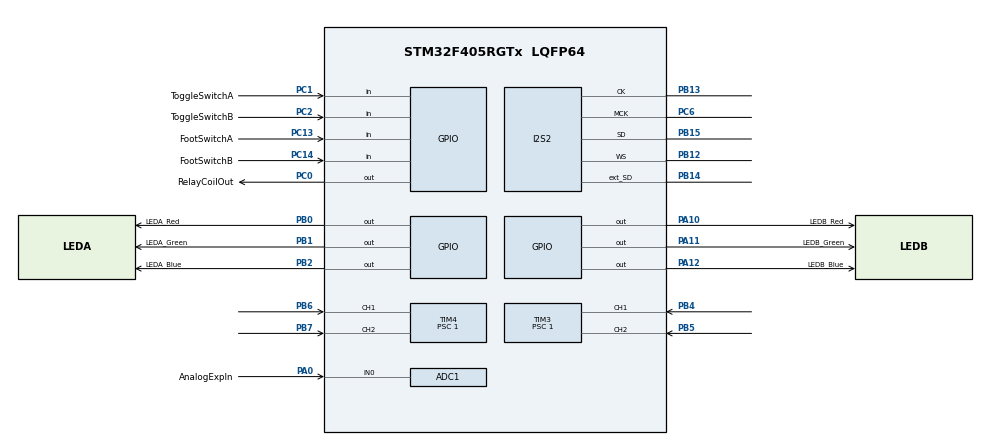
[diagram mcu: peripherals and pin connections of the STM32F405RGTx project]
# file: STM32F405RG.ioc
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Mcu.Family=STM32F4
Dma.I2S2_EXT_RX.1.PeriphInc=DMA_PINC_DISABLE
Dma.SPI2_TX.0.MemInc=DMA_MINC_ENABLE
RCC.CortexFreq_Value=168000000
TIM14.AutoReloadPreload=TIM_AUTORELOAD_PRELOAD_ENABLE
PC0.GPIO_Label=RelayCoilOut
PB0.GPIO_Label=LEDA_Red
NVIC.DMA1_Stream4_IRQn=true\:2\:0\:true\:false\:true\:false\:true
PB13.Signal=I2S2_CK
PB15.Signal=I2S2_SD
Dma.SPI2_TX.0.Instance=DMA1_Stream4
RCC.SYSCLKSource=RCC_SYSCLKSOURCE_PLLCLK
ProjectManager.StackSize=0x400
Dma.SPI2_TX.0.MemDataAlignment=DMA_MDATAALIGN_HALFWORD
Dma.I2S2_EXT_RX.1.Instance=DMA1_Stream3
PA12.Signal=GPIO_Output
RCC.HCLKFreq_Value=168000000
RCC.APB2TimFreq_Value=168000000
PB6.Signal=S_TIM4_CH1
Dma.SPI2_TX.0.Mode=DMA_CIRCULAR
RCC.AHBFreq_Value=168000000
ADC1.Channel-0\#ChannelRegularConversion=ADC_CHANNEL_0
RCC.HSE_VALUE=25000000
NVIC.TIM8_TRG_COM_TIM14_IRQn=true\:0\:0\:false\:false\:true\:true\:true
PB2.Signal=GPIO_Output
PB3.Mode=Trace_Asynchronous_SW
PC13-ANTI_TAMP.Signal=GPIO_Input
TIM14.Period=65535
PA14.Mode=Trace_Asynchronous_SW
PB14.Mode=Full_Duplex_Master
TIM3.Prescaler=1
PB1.GPIO_Label=LEDA_Green
PA10.GPIO_Label=LEDB_Red
SH.S_TIM4_CH2.0=TIM4_CH2,Encoder_Interface
PB7.Signal=S_TIM4_CH2
Dma.I2S2_EXT_RX.1.MemInc=DMA_MINC_ENABLE
SH.ADCx_IN0.0=ADC1_IN0,IN0
SH.S_TIM3_CH1.0=TIM3_CH1,Encoder_Interface
I2S2.DataFormat=I2S_DATAFORMAT_24B
ADC1.SamplingTime-0\#ChannelRegularConversion=ADC_SAMPLETIME_3CYCLES
Mcu.Package=LQFP64
PB1.Signal=GPIO_Output
PB12.Mode=Full_Duplex_Master
PA10.Signal=GPIO_Output
Dma.I2S2_EXT_RX.1.PeriphDataAlignment=DMA_PDATAALIGN_HALFWORD
Dma.SPI2_TX.0.PeriphInc=DMA_PINC_DISABLE
RCC.APB2CLKDivider=RCC_HCLK_DIV2
SH.S_TIM4_CH1.0=TIM4_CH1,Encoder_Interface
Dma.Request1=I2S2_EXT_RX
RCC.APB1TimFreq_Value=84000000
Dma.I2S2_EXT_RX.1.Priority=DMA_PRIORITY_LOW
PC14-OSC32_IN.GPIO_Label=FootSwitchB
PB13.Mode=Full_Duplex_Master
VP_TIM14_VS_ClockSourceINT.Mode=Enable_Timer
Dma.Request0=SPI2_TX
PC6.GPIO_Speed=GPIO_SPEED_FREQ_VERY_HIGH
PC2.GPIO_Label=ToggleSwitchB
PB4.Signal=S_TIM3_CH1
I2S2.AudioFreq=I2S_AUDIOFREQ_96K
ADC1.Rank-0\#ChannelRegularConversion=1
I2S2.Instance=SPI$Index
TIM3.AutoReloadPreload=TIM_AUTORELOAD_PRELOAD_ENABLE
PC13-ANTI_TAMP.GPIO_Label=FootSwitchA
PC2.Signal=GPIO_Input
PC6.Signal=I2S2_MCK
PA11.GPIO_Label=LEDB_Green
PC0.Signal=GPIO_Output
RCC.APB1CLKDivider=RCC_HCLK_DIV4
PC14-OSC32_IN.Signal=GPIO_Input
PA12.GPIO_Label=LEDB_Blue
PA0-WKUP.GPIO_Label=AnalogExpIn
PA0-WKUP.Signal=ADCx_IN0
PA13.Signal=SYS_JTMS-SWDIO
Dma.I2S2_EXT_RX.1.Mode=DMA_CIRCULAR
ProjectManager.TargetToolchain=STM32CubeIDE
PB14.GPIO_Speed=GPIO_SPEED_FREQ_VERY_HIGH
PC6.Mode=Master_Clock_Activated
I2S2.VirtualMode=I2S_MODE_MASTER
PB13.GPIO_Speed=GPIO_SPEED_FREQ_VERY_HIGH
TIM4.Prescaler=1
RCC.LSE_VALUE=32768
PB12.GPIO_Speed=GPIO_SPEED_FREQ_VERY_HIGH
PB14.Signal=I2S2_ext_SD
SH.S_TIM3_CH2.0=TIM3_CH2,Encoder_Interface
Dma.I2S2_EXT_RX.1.FIFOMode=DMA_FIFOMODE_DISABLE
board=custom
RCC.VCOOutputFreq_Value=336000000
PB15.Mode=Full_Duplex_Master
RCC.APB2Freq_Value=84000000
Dma.SPI2_TX.0.PeriphDataAlignment=DMA_PDATAALIGN_HALFWORD
PB15.GPIO_Speed=GPIO_SPEED_FREQ_VERY_HIGH
PC1.GPIO_Label=ToggleSwitchA
PA13.Mode=Trace_Asynchronous_SW
Mcu.Name=STM32F405RGTx
Dma.SPI2_TX.0.FIFOMode=DMA_FIFOMODE_DISABLE
TIM14.Prescaler=4096
I2S2.FullDuplexMode=I2S_FULLDUPLEXMODE_ENABLE
RCC.48MHZClocksFreq_Value=84000000
PB3.Signal=SYS_JTDO-SWO
Dma.SPI2_TX.0.Priority=DMA_PRIORITY_LOW
RCC.SYSCLKFreq_VALUE=168000000
PB5.Signal=S_TIM3_CH2
ADC1.master=1
I2S2.ErrorAudioFreq=-2.34 %
PA11.Signal=GPIO_Output
PA14.Signal=SYS_JTCK-SWCLK
PB2.GPIO_Label=LEDA_Blue
ProjectManager.HeapSize=0x200
RCC.HSI_VALUE=16000000
Dma.I2S2_EXT_RX.1.Direction=DMA_PERIPH_TO_MEMORY
NVIC.PriorityGroup=NVIC_PRIORITYGROUP_4
ADC1.NbrOfConversionFlag=1
RCC.PLLN=336
NVIC.DMA1_Stream3_IRQn=true\:2\:0\:true\:false\:true\:false\:true
Dma.SPI2_TX.0.Direction=DMA_MEMORY_TO_PERIPH
Dma.I2S2_EXT_RX.1.MemDataAlignment=DMA_MDATAALIGN_HALFWORD
RCC.APB1Freq_Value=42000000
PB0.Signal=GPIO_Output
I2S2.RealAudioFreq=93.75 KHz
PC1.Signal=GPIO_Input
PB12.Signal=I2S2_WS

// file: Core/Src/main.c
/* USER CODE BEGIN Header */
/**
  ******************************************************************************
  * @file           : main.c
  * @brief          : Main program body
  ******************************************************************************
  * @attention
  *
  * <h2><center>&copy; Copyright (c) 2022 STMicroelectronics.
  * All rights reserved.</center></h2>
  *
  * This software component is licensed by ST under BSD 3-Clause license,
  * the "License"; You may not use this file except in compliance with the
  * License. You may obtain a copy of the License at:
  *                        opensource.org/licenses/BSD-3-Clause
  *
  ******************************************************************************
  */
/* USER CODE END Header */
#include "main.h"
#include "adc.h"
#include "dma.h"
#include "i2s.h"
#include "tim.h"
#include "gpio.h"

/* USER CODE BEGIN Includes */
#include <mainapp.hpp>
/* USER CODE END Includes */

void SystemClock_Config(void);

int main(void)
{

  /* MCU Configuration--------------------------------------------------------*/

  /* Reset of all peripherals, Initializes the Flash interface and the Systick. */
  HAL_Init();

  /* Configure the system clock */
  SystemClock_Config();

  /* Initialize all configured peripherals */
  MX_GPIO_Init();
  MX_DMA_Init();
  MX_ADC1_Init();
  MX_I2S2_Init();
  MX_TIM3_Init();
  MX_TIM4_Init();
  MX_TIM14_Init();
  /* USER CODE BEGIN 2 */
  mainapp();

  /* USER CODE END 2 */

  /* Infinite loop */
  while (1)
  {

  }
}

void SystemClock_Config(void)
{
  LL_FLASH_SetLatency(LL_FLASH_LATENCY_5);
  while(LL_FLASH_GetLatency()!= LL_FLASH_LATENCY_5)
  {
  }
  LL_PWR_SetRegulVoltageScaling(LL_PWR_REGU_VOLTAGE_SCALE1);
  LL_RCC_HSI_SetCalibTrimming(16);
  LL_RCC_HSI_Enable();

   /* Wait till HSI is ready */
  while(LL_RCC_HSI_IsReady() != 1)
  {

  }
  LL_RCC_PLL_ConfigDomain_SYS(LL_RCC_PLLSOURCE_HSI, LL_RCC_PLLM_DIV_16, 336, LL_RCC_PLLP_DIV_2);
  LL_RCC_PLLI2S_ConfigDomain_I2S(LL_RCC_PLLSOURCE_HSI, LL_RCC_PLLI2SM_DIV_16, 192, LL_RCC_PLLI2SR_DIV_2);
  LL_RCC_PLL_Enable();

   /* Wait till PLL is ready */
  while(LL_RCC_PLL_IsReady() != 1)
  {

  }
  LL_RCC_PLLI2S_Enable();

   /* Wait till PLL is ready */
  while(LL_RCC_PLLI2S_IsReady() != 1)
  {

  }
  LL_RCC_SetAHBPrescaler(LL_RCC_SYSCLK_DIV_1);
  LL_RCC_SetAPB1Prescaler(LL_RCC_APB1_DIV_4);
  LL_RCC_SetAPB2Prescaler(LL_RCC_APB2_DIV_2);
  LL_RCC_SetSysClkSource(LL_RCC_SYS_CLKSOURCE_PLL);

   /* Wait till System clock is ready */
  while(LL_RCC_GetSysClkSource() != LL_RCC_SYS_CLKSOURCE_STATUS_PLL)
  {

  }
  LL_SetSystemCoreClock(168000000);

   /* Update the time base */
  if (HAL_InitTick (TICK_INT_PRIORITY) != HAL_OK)
  {
    Error_Handler();
  }
  LL_RCC_SetI2SClockSource(LL_RCC_I2S1_CLKSOURCE_PLLI2S);
}

void Error_Handler(void)
{
  __disable_irq();
  while (1)
  {
  }
}

/************************ (C) COPYRIGHT STMicroelectronics *****END OF FILE****/
